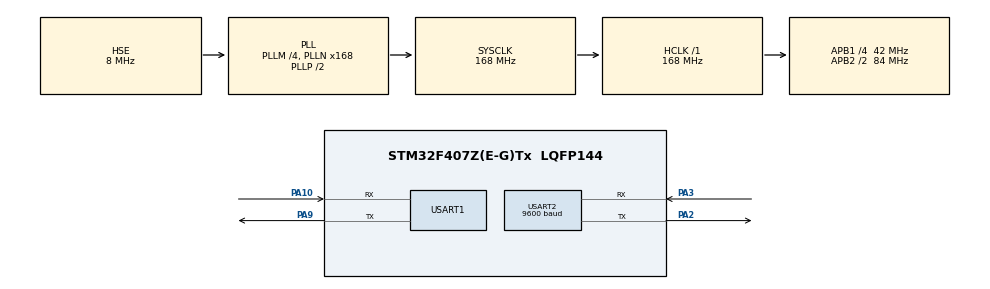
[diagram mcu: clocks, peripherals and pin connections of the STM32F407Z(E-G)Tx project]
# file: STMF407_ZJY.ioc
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FREERTOS.MEMORY_ALLOCATION=0
FREERTOS.Tasks01=sysTask,-2,128,StartSysTask,Default,NULL,Dynamic,NULL,NULL
FREERTOS.configTIMER_TASK_PRIORITY=6
FREERTOS.configTOTAL_HEAP_SIZE=51200
FREERTOS.configUSE_TIMERS=1
FREERTOS.configUSE_TRACE_FACILITY=0
Mcu.Family=STM32F4
Mcu.Name=STM32F407Z(E-G)Tx
Mcu.Package=LQFP144
NVIC.PriorityGroup=NVIC_PRIORITYGROUP_4
NVIC.TIM1_UP_TIM10_IRQn=true\:0\:0\:false\:false\:true\:false\:false\:true
NVIC.TimeBase=TIM1_UP_TIM10_IRQn
NVIC.TimeBaseIP=TIM1
NVIC.USART1_IRQn=true\:5\:0\:false\:false\:true\:true\:true\:true
NVIC.USART2_IRQn=true\:5\:0\:false\:false\:true\:true\:true\:true
PA10.Mode=Asynchronous
PA10.Signal=USART1_RX
PA2.Mode=Asynchronous
PA2.Signal=USART2_TX
PA3.Mode=Asynchronous
PA3.Signal=USART2_RX
PA9.Mode=Asynchronous
PA9.Signal=USART1_TX
PH0-OSC_IN.Mode=HSE-External-Oscillator
PH0-OSC_IN.Signal=RCC_OSC_IN
PH1-OSC_OUT.Mode=HSE-External-Oscillator
PH1-OSC_OUT.Signal=RCC_OSC_OUT
ProjectManager.HeapSize=0x200
ProjectManager.StackSize=0x400
ProjectManager.TargetToolchain=STM32CubeIDE
RCC.48MHZClocksFreq_Value=84000000
RCC.AHBFreq_Value=168000000
RCC.APB1CLKDivider=RCC_HCLK_DIV4
RCC.APB1Freq_Value=42000000
RCC.APB1TimFreq_Value=84000000
RCC.APB2CLKDivider=RCC_HCLK_DIV2
RCC.APB2Freq_Value=84000000
RCC.APB2TimFreq_Value=168000000
RCC.CortexFreq_Value=168000000
RCC.HCLKFreq_Value=168000000
RCC.HSE_VALUE=8000000
RCC.HSI_VALUE=16000000
RCC.LSE_VALUE=32768
RCC.PLLM=4
RCC.PLLN=168
RCC.PLLSourceVirtual=RCC_PLLSOURCE_HSE
RCC.SYSCLKFreq_VALUE=168000000
RCC.SYSCLKSource=RCC_SYSCLKSOURCE_PLLCLK
RCC.VCOOutputFreq_Value=336000000
USART1.VirtualMode=VM_ASYNC
USART2.BaudRate=9600
USART2.Parity=PARITY_NONE
USART2.VirtualMode=VM_ASYNC
VP_FREERTOS_VS_CMSIS_V1.Mode=CMSIS_V1
VP_SYS_VS_tim1.Mode=TIM1
board=custom

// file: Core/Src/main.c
/* USER CODE BEGIN Header */
/**
  ******************************************************************************
  * @file           : main.c
  * @brief          : Main program body
  ******************************************************************************
  * @attention
  *
  * <h2><center>&copy; Copyright (c) 2020 STMicroelectronics.
  * All rights reserved.</center></h2>
  *
  * This software component is licensed by ST under BSD 3-Clause license,
  * the "License"; You may not use this file except in compliance with the
  * License. You may obtain a copy of the License at:
  *                        opensource.org/licenses/BSD-3-Clause
  *
  ******************************************************************************
  */
/* USER CODE END Header */

#include "main.h"
#include "cmsis_os.h"
#include "usart.h"
#include "gpio.h"

/* USER CODE BEGIN Includes */
#include <stdio.h>
#include "hlw8032.h"
#include "uartest.h"
/* USER CODE END Includes */

/* USER CODE BEGIN PD */
uint8_t FIRMWARE_VERSION[] = "1.0.0";
/* USER CODE END PD */

void SystemClock_Config(void);
void MX_FREERTOS_Init(void);

/* USER CODE BEGIN 0 */
static void log_Print(void);
/* USER CODE END 0 */

int main(void)
{

  /* MCU Configuration--------------------------------------------------------*/

  /* Reset of all peripherals, Initializes the Flash interface and the Systick. */
  HAL_Init();

  /* Configure the system clock */
  SystemClock_Config();

  /* Initialize all configured peripherals */
  MX_GPIO_Init();
  MX_USART1_UART_Init();
  MX_USART2_UART_Init();
  /* USER CODE BEGIN 2 */
  uartest_init();
  /* USER CODE END 2 */

  /* Call init function for freertos objects (in freertos.c) */
  MX_FREERTOS_Init();

  /* Start scheduler */
  osKernelStart();

  /* We should never get here as control is now taken by the scheduler */

  /* Infinite loop */
  while (1)
  {

  }
}

void SystemClock_Config(void)
{
  RCC_OscInitTypeDef RCC_OscInitStruct = {0};
  RCC_ClkInitTypeDef RCC_ClkInitStruct = {0};

  /** Configure the main internal regulator output voltage
  */
  __HAL_RCC_PWR_CLK_ENABLE();
  __HAL_PWR_VOLTAGESCALING_CONFIG(PWR_REGULATOR_VOLTAGE_SCALE1);
  /** Initializes the CPU, AHB and APB busses clocks
  */
  RCC_OscInitStruct.OscillatorType = RCC_OSCILLATORTYPE_HSE;
  RCC_OscInitStruct.HSEState = RCC_HSE_ON;
  RCC_OscInitStruct.PLL.PLLState = RCC_PLL_ON;
  RCC_OscInitStruct.PLL.PLLSource = RCC_PLLSOURCE_HSE;
  RCC_OscInitStruct.PLL.PLLM = 4;
  RCC_OscInitStruct.PLL.PLLN = 168;
  RCC_OscInitStruct.PLL.PLLP = RCC_PLLP_DIV2;
  RCC_OscInitStruct.PLL.PLLQ = 4;
  if (HAL_RCC_OscConfig(&RCC_OscInitStruct) != HAL_OK)
  {
    Error_Handler();
  }
  /** Initializes the CPU, AHB and APB busses clocks
  */
  RCC_ClkInitStruct.ClockType = RCC_CLOCKTYPE_HCLK|RCC_CLOCKTYPE_SYSCLK
                              |RCC_CLOCKTYPE_PCLK1|RCC_CLOCKTYPE_PCLK2;
  RCC_ClkInitStruct.SYSCLKSource = RCC_SYSCLKSOURCE_PLLCLK;
  RCC_ClkInitStruct.AHBCLKDivider = RCC_SYSCLK_DIV1;
  RCC_ClkInitStruct.APB1CLKDivider = RCC_HCLK_DIV4;
  RCC_ClkInitStruct.APB2CLKDivider = RCC_HCLK_DIV2;

  if (HAL_RCC_ClockConfig(&RCC_ClkInitStruct, FLASH_LATENCY_5) != HAL_OK)
  {
    Error_Handler();
  }
}

/* USER CODE BEGIN 4 */
static void log_Print(void)
{
	printf("Firmware version:%s\n", FIRMWARE_VERSION);
}
/* USER CODE END 4 */

void HAL_TIM_PeriodElapsedCallback(TIM_HandleTypeDef *htim)
{
  if (htim->Instance == TIM1) {
    HAL_IncTick();
  }
}

void Error_Handler(void)
{
}

/************************ (C) COPYRIGHT STMicroelectronics *****END OF FILE****/

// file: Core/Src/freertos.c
/* USER CODE BEGIN Header */
/**
  ******************************************************************************
  * File Name          : freertos.c
  * Description        : Code for freertos applications
  ******************************************************************************
  * @attention
  *
  * <h2><center>&copy; Copyright (c) 2020 STMicroelectronics.
  * All rights reserved.</center></h2>
  *
  * This software component is licensed by ST under Ultimate Liberty license
  * SLA0044, the "License"; You may not use this file except in compliance with
  * the License. You may obtain a copy of the License at:
  *                             www.st.com/SLA0044
  *
  ******************************************************************************
  */
/* USER CODE END Header */

#include "FreeRTOS.h"
#include "task.h"
#include "main.h"
#include "cmsis_os.h"

osThreadId sysTaskHandle;

void StartSysTask(void const * argument);

void MX_FREERTOS_Init(void); /* (MISRA C 2004 rule 8.1) */

void MX_FREERTOS_Init(void) {

  /* Create the thread(s) */
  /* definition and creation of sysTask */
  osThreadDef(sysTask, StartSysTask, osPriorityLow, 0, 128);
  sysTaskHandle = osThreadCreate(osThread(sysTask), NULL);

}

void StartSysTask(void const * argument)
{
  /* USER CODE BEGIN StartSysTask */
  /* Infinite loop */
  for(;;)
  {
    osDelay(1000);
  }
  /* USER CODE END StartSysTask */
}

/************************ (C) COPYRIGHT STMicroelectronics *****END OF FILE****/
